AUTOSAR XML (schema 4-0-3)
standard types defined: Boolean, UInt32, UInt8
package /AUTOSAR_Platform/DataConstrs
  range DC_Boolean: raw 0..1
  range DC_UInt8: raw 0..255
package /PATAC/MSM/ComponentTypes
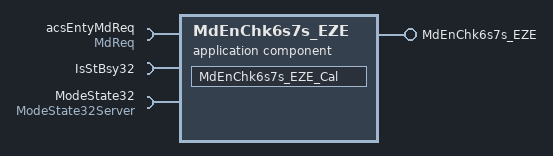
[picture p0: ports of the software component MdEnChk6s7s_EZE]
  application sw component type MdEnChk6s7s_EZE
    provide port MdEnChk6s7s_EZE: server-com-spec{operation=Cal, queue-length=1}, provided-interface=MdEnChk6s7s_EZE
    require port acsEntyMdReq: nonqueued-receiver-com-spec{data-element=Val, filter=data-filter-type=ALWAYS, init-value=0}, required-interface=MdReq
    require port IsStBsy32: required-com-specs=[IsStBsy32/Clear, IsStBsy32/Get, IsStBsy32/Set], required-interface=IsStBsy32
    require port ModeState32: required-com-specs=[ModeState32Server/Clear, ModeState32Server/Get, ModeState32Server/Set], required-interface=ModeState32Server
    behavior MdEnChk6s7s_EZE_InternalBehavior
      operation invoked event OIT_MdEnChk6s7s_EZE_Cal_MdEnChk6s7s_EZE_Cal: start-on-event=MdEnChk6s7s_EZE_Cal, operation=MdEnChk6s7s_EZE.Cal
      runnable MdEnChk6s7s_EZE_Cal
        data-receive-point-by-arguments:
          access REC_acsEntyMdReq_Val: accessed-variable=acsEntyMdReq.Val
        sync call SC_IsStBsy32_Get: operation=IsStBsy32.Get, timeout=0
        sync call SC_IsStBsy32_Set: operation=IsStBsy32.Set, timeout=0
        sync call SC_ModeState32_Set: operation=ModeState32.Set, timeout=0
  swc implementation MdEnChk6s7s_EZE_Implementation: behavior=MdEnChk6s7s_EZE_InternalBehavior
    code-descriptors:
      code Default: artifact-descriptors=autosar-engineering-object={short-label=Default, category=SWSRC}
package /PATAC/MSM/ModeAdjust/PortInterface
  client server interface IsStBsy32
    operation Clear
      arg ClearBit: type=UInt32, direction=IN, server-argument-impl-policy=USE-ARGUMENT-TYPE
    operation Get
      arg IsStBsy32Bit: type=UInt32, direction=OUT, server-argument-impl-policy=USE-ARGUMENT-TYPE
    operation Set
      arg SetBit: type=UInt32, direction=IN, server-argument-impl-policy=USE-ARGUMENT-TYPE
  client server interface MdEnChk6s7s_EZE
    operation Cal  # StNun: 0 :4s 1:6s 2:7s 3:4sp
      arg StNum: type=UInt8, direction=IN, server-argument-impl-policy=USE-ARGUMENT-TYPE
  client server interface ModeState32Server
    operation Clear
      arg ClearBit: type=UInt32, direction=IN, server-argument-impl-policy=USE-ARGUMENT-TYPE
    operation Get
      arg MdEn32: type=UInt32, direction=OUT, server-argument-impl-policy=USE-ARGUMENT-TYPE
    operation Set
      arg SetBit: type=UInt32, direction=IN, server-argument-impl-policy=USE-ARGUMENT-TYPE
  sender receiver interface MdReq: invalidation-policy{data-element=Val, handle-invalid=DONT-INVALIDATE}
    data Val: type=Boolean
